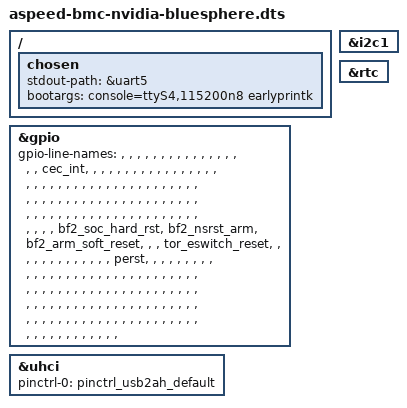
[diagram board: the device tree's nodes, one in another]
// SPDX-License-Identifier: GPL-2.0+
/dts-v1/;

#include "aspeed-bmc-nvidia-bluesphere-base.dtsi"

/ {
	chosen {
		stdout-path = &uart5;
		bootargs = "console=ttyS4,115200n8 earlyprintk";
	};
};

&gpio {
	gpio-line-names =
	/*A0-A7*/       "","","","","","","","",
	/*B0-B7*/       "","","","","","","","",
	/*C0-C7*/       "","cec_int","","","","","","",
	/*D0-D7*/       "","","","","","","","",
	/*E0-E7*/       "","","","","","","","",
	/*F0-F7*/       "","","","","","","","",
	/*G0-G7*/       "","","","","","","","",
	/*H0-H7*/       "","","","","","","","",
	/*I0-I7*/       "","","","","","","","",
	/*J0-J7*/       "","","","","","","","",
	/*K0-K7*/       "","","","","","","","",
	/*L0-L7*/       "","","","","","","","",
	/*M0-M7*/       "","","","","","","","",
	/*N0-N7*/       "bf2_soc_hard_rst","bf2_nsrst_arm","bf2_arm_soft_reset","","","tor_eswitch_reset","","",
	/*O0-O7*/       "","","","","","","","",
	/*P0-P7*/       "","","perst","","","","","",
	/*Q0-Q7*/       "","","","","","","","",
	/*R0-R7*/       "","","","","","","","",
	/*S0-S7*/       "","","","","","","","",
	/*T0-T7*/       "","","","","","","","",
	/*U0-U7*/       "","","","","","","","",
	/*V0-V7*/       "","","","","","","","",
	/*W0-W7*/       "","","","","","","","",
	/*X0-X7*/       "","","","","","","","",
	/*Y0-Y7*/       "","","","","","","","",
	/*Z0-Z7*/       "","","","","","","","",
	/*AA0-AA7*/     "","","","","","","","",
	/*AB0-AB7*/     "","","","","","","","",
	/*AC0-AC7*/     "","","","","","","","";

};

&i2c1 {
	status = "okay";
};

&uhci {
	status = "okay";
	pinctrl-names = "default";
	pinctrl-0 = <&pinctrl_usb2ah_default>;
};

&rtc {
	status = "okay";
};
